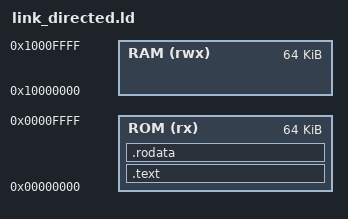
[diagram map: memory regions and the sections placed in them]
ENTRY(_start)

MEMORY
{
    ROM (rx)  : ORIGIN = 0x00000000, LENGTH = 64K
    RAM (rwx) : ORIGIN = 0x10000000, LENGTH = 64K
}

SECTIONS
{
    .text : ALIGN(4)
    {
        KEEP(*(.text.init))
        *(.text*)
    } > ROM

    .rodata : ALIGN(4)
    {
        *(.rodata*)
    } > ROM
}
